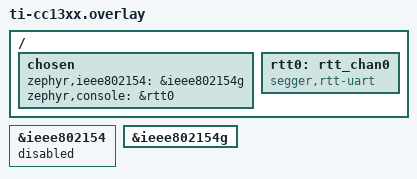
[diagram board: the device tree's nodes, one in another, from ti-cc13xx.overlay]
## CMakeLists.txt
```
cmake_minimum_required(VERSION 3.20.0)

find_package(Zephyr REQUIRED HINTS $ENV{ZEPHYR_BASE})
project(tsch)

target_sources(app PRIVATE src/main.c)
```

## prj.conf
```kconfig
# L3+: Minimal networking
CONFIG_NETWORKING=y
CONFIG_NET_IPV4=n
CONFIG_NET_IPV6=n
CONFIG_NET_CONFIG_SETTINGS=y

# L2: IEEE 802.15.4 MAC
CONFIG_NET_L2_IEEE802154=y
CONFIG_NET_L2_IEEE802154_SECURITY=y

# L2: IEEE 802.15.4 TSCH
CONFIG_NET_L2_IEEE802154_TSCH=y
CONFIG_NUM_COOP_PRIORITIES=1

# L1: IEEE 802.15.4 PHY
# Assuming driver implements channel page zero!
# 868 MHz band (Europe)
CONFIG_NET_CONFIG_IEEE802154_CHANNEL_RANGE_FROM=0
CONFIG_NET_CONFIG_IEEE802154_CHANNEL_RANGE_TO=0
# 915 MHz band (US)
# CONFIG_NET_CONFIG_IEEE802154_CHANNEL_RANGE_FROM=1
# CONFIG_NET_CONFIG_IEEE802154_CHANNEL_RANGE_TO=10
# 2.4 GHz band
# CONFIG_NET_CONFIG_IEEE802154_CHANNEL_RANGE_FROM=11
# CONFIG_NET_CONFIG_IEEE802154_CHANNEL_RANGE_TO=26
CONFIG_NET_CONFIG_IEEE802154_RADIO_TX_POWER=-20

# Power Management
CONFIG_PM=y
CONFIG_PM_DEVICE=y
CONFIG_PM_DEVICE_RUNTIME=y

# Logging: Basics
# CONFIG_LOG=y
# CONFIG_NET_LOG=y
# CONFIG_PRINTK=n
# CONFIG_BOOT_BANNER=n # Required to disable printk.
# CONFIG_LOG_BUFFER_SIZE=2048
# CONFIG_NET_L2_IEEE802154_LOG_LEVEL_INF=y
# CONFIG_IEEE802154_DRIVER_LOG_LEVEL_INF=y

# Logging: Sync
# CONFIG_LOG_MODE_IMMEDIATE=y

# Logging: Async
# CONFIG_UART_RTT=y
# CONFIG_UART_ASYNC_API=y
# CONFIG_LOG_BACKEND_UART_ASYNC=y

# Shell
# CONFIG_SHELL=y
# CONFIG_NET_SHELL=y
# CONFIG_NET_L2_IEEE802154_SHELL=y
# CONFIG_UART_CONSOLE=n

# Kernel
CONFIG_INIT_STACKS=y
CONFIG_IDLE_STACK_SIZE=2048
CONFIG_MAIN_STACK_SIZE=2048
CONFIG_ENTROPY_GENERATOR=y

# Debugging
CONFIG_ASSERT=y
CONFIG_ASSERT_NO_COND_INFO=y
CONFIG_WARN_EXPERIMENTAL=y
CONFIG_COMPAT_INCLUDES=n
CONFIG_DEBUG_OPTIMIZATIONS=y
CONFIG_DEBUG_THREAD_INFO=y
CONFIG_COMPILER_TRACK_MACRO_EXPANSION=n

# Tracing
CONFIG_TRACING=y
CONFIG_THREAD_NAME=y
CONFIG_USE_SEGGER_RTT=y
CONFIG_SEGGER_SYSTEMVIEW=y
CONFIG_TRACING_SEMAPHORE=n
CONFIG_TRACING_MUTEX=n
CONFIG_TRACING_TIMER=n
CONFIG_TRACING_PM=n
```

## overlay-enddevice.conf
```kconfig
CONFIG_NET_CONFIG_IEEE802154_DEVICE_ROLE_ENDDEVICE=y
CONFIG_NET_L2_IEEE802154_RFD=y
```

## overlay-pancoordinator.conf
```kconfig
CONFIG_NET_CONFIG_IEEE802154_DEVICE_ROLE_PAN_COORDINATOR=y
CONFIG_NET_L2_IEEE802154_FFD=y
```

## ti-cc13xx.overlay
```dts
/ {
	chosen {
		zephyr,ieee802154 = &ieee802154g;
		zephyr,console = &rtt0;
	};

	rtt0: rtt_chan0 {
		compatible = "segger,rtt-uart";
		status = "okay";
	};
};

/* &radio {
	debug-pins = "all";
}; */

&ieee802154 {
	status = "disabled";
};

&ieee802154g {
	status = "okay";
};
```

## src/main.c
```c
#include <zephyr/net/net_if.h>
#include <zephyr/net/net_l2.h>
#include <zephyr/net/ieee802154_mgmt.h>

static uint8_t broadcast_address_be[] = {0xff, 0xff};
static struct ieee802154_tsch_link link = {
	.slotframe_handle = 0,
	.timeslot = 1,
	.node_addr = {.addr = broadcast_address_be,
		      .len = IEEE802154_SHORT_ADDR_LENGTH,
		      .type = NET_LINK_IEEE802154},
	.rx = 1,
};


int main(void)
{
	struct net_if *iface = net_if_get_first_by_type(&NET_L2_GET_NAME(IEEE802154));
	uint16_t device_role;

	/* Basic configuration should have done by the net config framework (see
	 * ieee802154_settings.c):
	 *  * a default slotframe
	 *  * channel hopping and template timing - depending on the configured
	 *    PHY and channel page.
	 *  * for (PAN) coordinators only: a single beacon TX link, otherwise no
	 *    link
	 *
	 * We only assert that the interface is up initially.
	 */
	__ASSERT_NO_MSG(net_if_is_up(iface));

	net_mgmt(NET_REQUEST_IEEE802154_GET_DEVICE_ROLE, iface, &device_role, sizeof(device_role));
	link.handle = device_role == IEEE802154_DEVICE_ROLE_ENDDEVICE ? 0 : 1;
	net_mgmt(NET_REQUEST_IEEE802154_SET_TSCH_LINK, iface, &link, sizeof(void *));

	return 0;
}
```
